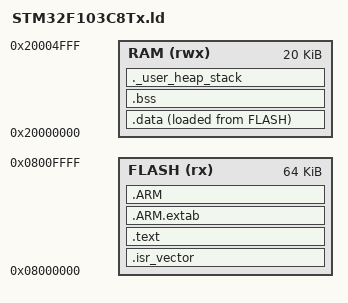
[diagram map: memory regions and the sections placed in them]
/* ~/STM32_Project/Project_5_1/linker/STM32F103C8Tx.ld */
ENTRY(Reset_Handler)

/* 定义栈顶符号 _estack = RAM 起始地址 + RAM 大小 */
_estack = ORIGIN(RAM) + LENGTH(RAM);

MEMORY
{
    FLASH (rx)      : ORIGIN = 0x08000000, LENGTH = 64K
    RAM (rwx)       : ORIGIN = 0x20000000, LENGTH = 20K
}

SECTIONS
{
    .isr_vector :
    {
        . = ALIGN(4);
        KEEP(*(.isr_vector))
        . = ALIGN(4);
    } >FLASH

    .text :
    {
        . = ALIGN(4);
        *(.text)
        *(.text*)
        *(.rodata)
        *(.rodata*)
        . = ALIGN(4);
        _etext = .;
    } >FLASH

    .ARM.extab :
    {
        *(.ARM.extab* .gnu.linkonce.armextab.*)
    } >FLASH

    .ARM :
    {
        __exidx_start = .;
        *(.ARM.exidx*)
        __exidx_end = .;
    } >FLASH

    _sidata = .;

    .data :
    {
        . = ALIGN(4);
        _sdata = .;
        *(.data)
        *(.data*)
        . = ALIGN(4);
        _edata = .;
    } >RAM AT > FLASH

    .bss :
    {
        . = ALIGN(4);
        _sbss = .;
        __bss_start__ = _sbss;
        *(.bss)
        *(.bss*)
        *(COMMON)
        . = ALIGN(4);
        _ebss = .;
        __bss_end__ = _ebss;
    } >RAM

    ._user_heap_stack :
    {
        . = ALIGN(8);
        . = . + 0x400; /* Heap 1KB */
        . = . + 0x400; /* Stack 1KB */
        . = ALIGN(8);
    } >RAM

    /DISCARD/ :
    {
        libc.a(*)
        libm.a(*)
        libgcc.a(*)
    }
}
